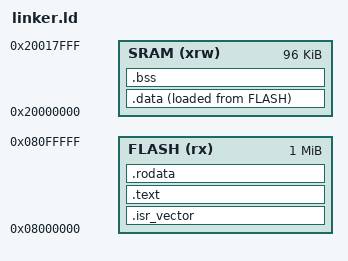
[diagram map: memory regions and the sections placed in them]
ENTRY(Reset_Handler)

/* memory layout for an STM32L476RG */
MEMORY
{
  FLASH (rx)  : ORIGIN = 0x08000000, LENGTH = 0x100000
  SRAM (xrw)  : ORIGIN = 0x20000000, LENGTH = 0x18000
}
/* End of SRAM for top of stack */
_sram_end = 0x20000000 + 0x18000;

/* Sections */
SECTIONS
{
  .isr_vector :
  {
    . = ALIGN(4);
    KEEP(*(.isr_vector))
    . = ALIGN(4);
  } >FLASH

  .text :
  {
    . = ALIGN(4);
    *(.text)           /* .text sections (code) */
    *(.text*)         /* .text sections (code) */
    *(.rodata)         /* .rodata sections (constants, strings, etc.) */
    *(.rodata*)       /* .rodata sections (constants, strings, etc.) */
    . = ALIGN(4);
  } >FLASH

  .rodata :
  {
    . = ALIGN(4);
    *(.rodata)         /* .rodata sections (constants, strings, etc.) */
    *(.rodata*)        /* .rodata* sections (constants, strings, etc.) */
    . = ALIGN(4);
  } >FLASH

  _sidata = LOADADDR(.data);
  .data :
  {
    . = ALIGN(4);
    _sdata = .;        /* create a global symbol at data start */
    *(.data)           /* .data sections */
    *(.data*)          /* .data* sections */
    . = ALIGN(4);
    _edata = .;        /* define a global symbol at data end */
  } >SRAM AT> FLASH

  .bss :
  {
    . = ALIGN(4);
    _sbss = .;
    *(.bss)
    *(.bss*)
    *(COMMON)
    . = ALIGN(4);
    _ebss = .;
  } >SRAM
}
